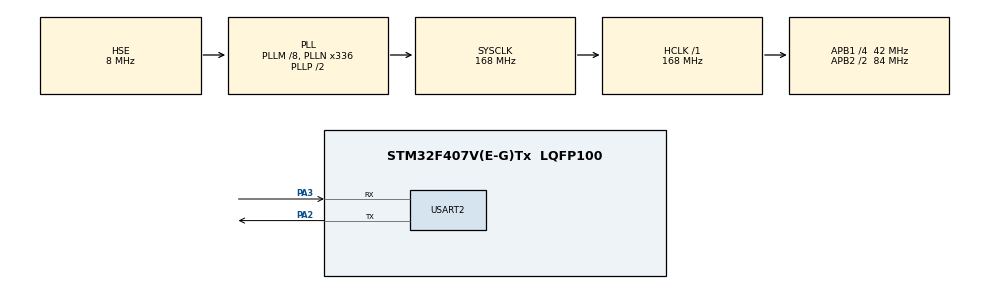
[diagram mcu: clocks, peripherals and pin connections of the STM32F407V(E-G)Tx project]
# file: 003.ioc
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Mcu.Family=STM32F4
Mcu.Name=STM32F407V(E-G)Tx
Mcu.Package=LQFP100
NVIC.PriorityGroup=NVIC_PRIORITYGROUP_0
NVIC.USART2_IRQn=true\:0\:0\:false\:false\:true\:true\:true\:true
PA2.Mode=Asynchronous
PA2.Signal=USART2_TX
PA3.Mode=Asynchronous
PA3.Signal=USART2_RX
PH0-OSC_IN.Mode=HSE-External-Oscillator
PH0-OSC_IN.Signal=RCC_OSC_IN
PH1-OSC_OUT.Mode=HSE-External-Oscillator
PH1-OSC_OUT.Signal=RCC_OSC_OUT
ProjectManager.HeapSize=0x200
ProjectManager.StackSize=0x400
ProjectManager.TargetToolchain=STM32CubeIDE
RCC.48MHZClocksFreq_Value=48000000
RCC.AHBFreq_Value=168000000
RCC.APB1CLKDivider=RCC_HCLK_DIV4
RCC.APB1Freq_Value=42000000
RCC.APB1TimFreq_Value=84000000
RCC.APB2CLKDivider=RCC_HCLK_DIV2
RCC.APB2Freq_Value=84000000
RCC.APB2TimFreq_Value=168000000
RCC.CortexFreq_Value=168000000
RCC.HCLKFreq_Value=168000000
RCC.HSE_VALUE=8000000
RCC.HSI_VALUE=16000000
RCC.PLLM=8
RCC.PLLN=336
RCC.PLLQ=7
RCC.PLLSourceVirtual=RCC_PLLSOURCE_HSE
RCC.SYSCLKFreq_VALUE=168000000
RCC.SYSCLKSource=RCC_SYSCLKSOURCE_PLLCLK
RCC.VCOOutputFreq_Value=336000000
USART2.VirtualMode=VM_ASYNC
VP_RTC_VS_RTC_Activate.Mode=RTC_Enabled
VP_RTC_VS_RTC_Calendar.Mode=RTC_Calendar
board=STM32F407G-DISC1

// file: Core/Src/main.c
/* USER CODE BEGIN Header */
/**
  ******************************************************************************
  * @file           : main.c
  * @brief          : Main program body
  ******************************************************************************
  * @attention
  *
  * Copyright (c) 2026 STMicroelectronics.
  * All rights reserved.
  *
  * This software is licensed under terms that can be found in the LICENSE file
  * in the root directory of this software component.
  * If no LICENSE file comes with this software, it is provided AS-IS.
  *
  ******************************************************************************
  */
/* USER CODE END Header */
#include "main.h"

RTC_HandleTypeDef hrtc;

UART_HandleTypeDef huart2;

/* USER CODE BEGIN PV */
uint8_t rx_byte;
uint8_t rx_buf[4];
uint8_t rx_idx = 0;

RTC_TimeTypeDef sTime = {0};
RTC_DateTypeDef sDate = {0};
/* USER CODE END PV */

void SystemClock_Config(void);
static void MX_GPIO_Init(void);
static void MX_RTC_Init(void);
static void MX_USART2_UART_Init(void);

int main(void)
{

  /* MCU Configuration--------------------------------------------------------*/

  /* Reset of all peripherals, Initializes the Flash interface and the Systick. */
  HAL_Init();

  /* Configure the system clock */
  SystemClock_Config();

  /* Initialize all configured peripherals */
  MX_GPIO_Init();
  MX_RTC_Init();
  MX_USART2_UART_Init();
  /* USER CODE BEGIN 2 */
  // 2. 开启 USART1 接收中断 (每次接收 1 字节)
  HAL_UART_Receive_IT(&huart2, &rx_byte, 1);

  RCC->AHB1ENR |= (1 << 3);
  GPIOD->MODER &= ~(3 << (13 * 2));
  GPIOD->MODER |= (1 << (13 * 2));
  GPIOD->ODR |= (1 << 13);
  /* USER CODE END 2 */

  /* Infinite loop */
  while (1)
  {

    /* USER CODE BEGIN 3 */
	  HAL_Delay(100);
  }
  /* USER CODE END 3 */
}

void SystemClock_Config(void)
{
  RCC_OscInitTypeDef RCC_OscInitStruct = {0};
  RCC_ClkInitTypeDef RCC_ClkInitStruct = {0};

  /** Configure the main internal regulator output voltage
  */
  __HAL_RCC_PWR_CLK_ENABLE();
  __HAL_PWR_VOLTAGESCALING_CONFIG(PWR_REGULATOR_VOLTAGE_SCALE1);

  /** Initializes the RCC Oscillators according to the specified parameters
  * in the RCC_OscInitTypeDef structure.
  */
  RCC_OscInitStruct.OscillatorType = RCC_OSCILLATORTYPE_LSI|RCC_OSCILLATORTYPE_HSE;
  RCC_OscInitStruct.HSEState = RCC_HSE_ON;
  RCC_OscInitStruct.LSIState = RCC_LSI_ON;
  RCC_OscInitStruct.PLL.PLLState = RCC_PLL_ON;
  RCC_OscInitStruct.PLL.PLLSource = RCC_PLLSOURCE_HSE;
  RCC_OscInitStruct.PLL.PLLM = 8;
  RCC_OscInitStruct.PLL.PLLN = 336;
  RCC_OscInitStruct.PLL.PLLP = RCC_PLLP_DIV2;
  RCC_OscInitStruct.PLL.PLLQ = 7;
  if (HAL_RCC_OscConfig(&RCC_OscInitStruct) != HAL_OK)
  {
    Error_Handler();
  }

  /** Initializes the CPU, AHB and APB buses clocks
  */
  RCC_ClkInitStruct.ClockType = RCC_CLOCKTYPE_HCLK|RCC_CLOCKTYPE_SYSCLK
                              |RCC_CLOCKTYPE_PCLK1|RCC_CLOCKTYPE_PCLK2;
  RCC_ClkInitStruct.SYSCLKSource = RCC_SYSCLKSOURCE_PLLCLK;
  RCC_ClkInitStruct.AHBCLKDivider = RCC_SYSCLK_DIV1;
  RCC_ClkInitStruct.APB1CLKDivider = RCC_HCLK_DIV4;
  RCC_ClkInitStruct.APB2CLKDivider = RCC_HCLK_DIV2;

  if (HAL_RCC_ClockConfig(&RCC_ClkInitStruct, FLASH_LATENCY_5) != HAL_OK)
  {
    Error_Handler();
  }
}

static void MX_RTC_Init(void)
{

  RTC_TimeTypeDef sTime = {0};
  RTC_DateTypeDef sDate = {0};

  /** Initialize RTC Only
  */
  hrtc.Instance = RTC;
  hrtc.Init.HourFormat = RTC_HOURFORMAT_24;
  hrtc.Init.AsynchPrediv = 127;
  hrtc.Init.SynchPrediv = 255;
  hrtc.Init.OutPut = RTC_OUTPUT_DISABLE;
  hrtc.Init.OutPutPolarity = RTC_OUTPUT_POLARITY_HIGH;
  hrtc.Init.OutPutType = RTC_OUTPUT_TYPE_OPENDRAIN;
  if (HAL_RTC_Init(&hrtc) != HAL_OK)
  {
    Error_Handler();
  }

  /** Initialize RTC and set the Time and Date
  */
  sTime.Hours = 0x0;
  sTime.Minutes = 0x0;
  sTime.Seconds = 0x0;
  sTime.DayLightSaving = RTC_DAYLIGHTSAVING_NONE;
  sTime.StoreOperation = RTC_STOREOPERATION_RESET;
  if (HAL_RTC_SetTime(&hrtc, &sTime, RTC_FORMAT_BCD) != HAL_OK)
  {
    Error_Handler();
  }
  sDate.WeekDay = RTC_WEEKDAY_MONDAY;
  sDate.Month = RTC_MONTH_JANUARY;
  sDate.Date = 0x1;
  sDate.Year = 0x0;

  if (HAL_RTC_SetDate(&hrtc, &sDate, RTC_FORMAT_BCD) != HAL_OK)
  {
    Error_Handler();
  }

}

static void MX_USART2_UART_Init(void)
{

  huart2.Instance = USART2;
  huart2.Init.BaudRate = 115200;
  huart2.Init.WordLength = UART_WORDLENGTH_8B;
  huart2.Init.StopBits = UART_STOPBITS_1;
  huart2.Init.Parity = UART_PARITY_NONE;
  huart2.Init.Mode = UART_MODE_TX_RX;
  huart2.Init.HwFlowCtl = UART_HWCONTROL_NONE;
  huart2.Init.OverSampling = UART_OVERSAMPLING_16;
  if (HAL_UART_Init(&huart2) != HAL_OK)
  {
    Error_Handler();
  }

}

static void MX_GPIO_Init(void)
{

  /* GPIO Ports Clock Enable */
  __HAL_RCC_GPIOH_CLK_ENABLE();
  __HAL_RCC_GPIOA_CLK_ENABLE();

}

/* USER CODE BEGIN 4 */
// 串口接收中断回调函数
void HAL_UART_RxCpltCallback(UART_HandleTypeDef *huart)
{
    if (huart->Instance == USART2) { /* 切换为 USART2 */
        // 收到帧头 0xAA 启动解析
        if (rx_byte == 0xAA) {
            rx_idx = 0;
            rx_buf[rx_idx++] = rx_byte;
        } else if (rx_idx > 0) {
            rx_buf[rx_idx++] = rx_byte;
            // 收到 3 字节完整请求帧 (0xAA 0x01 0x55)
            if (rx_idx == 3 && rx_buf[2] == 0x55) {
                // 读取 RTC 时间并打包回传
                RTC_TimeTypeDef sTime = {0};
                RTC_DateTypeDef sDate = {0};
                HAL_RTC_GetTime(&hrtc, &sTime, RTC_FORMAT_BIN);
                HAL_RTC_GetDate(&hrtc, &sDate, RTC_FORMAT_BIN);

                uint8_t tx_buf[7] = {0xAA, sTime.Hours, sTime.Minutes, sTime.Seconds, 0x00, 0x00, 0x55};
                HAL_UART_Transmit(&huart2, tx_buf, 7, 100);

                rx_idx = 0; // 重置索引
            }
        }
        // 重新开启 USART2 接收中断
        HAL_UART_Receive_IT(&huart2, &rx_byte, 1);
    }
}

/* 3. 更新 USART2 错误防卡死回调 */
void HAL_UART_ErrorCallback(UART_HandleTypeDef *huart)
{
    if (huart->Instance == USART2) {
        __HAL_UART_CLEAR_OREFLAG(huart);
        __HAL_UART_CLEAR_NEFLAG(huart);
        __HAL_UART_CLEAR_FEFLAG(huart);

        HAL_UART_Receive_IT(&huart2, &rx_byte, 1);
    }
}
/* USER CODE END 4 */

void Error_Handler(void)
{
  __disable_irq();
  while (1)
  {
  }
}
